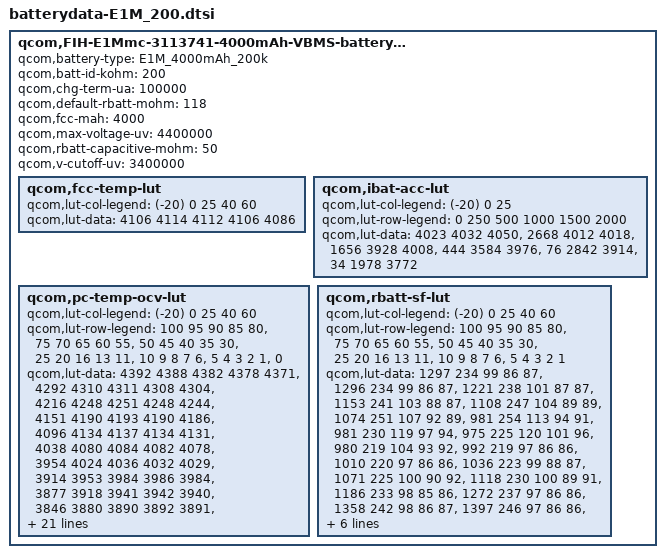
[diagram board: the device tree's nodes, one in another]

qcom,FIH-E1Mmc-3113741-4000mAh-VBMS-batterydata {
	qcom,battery-type = "E1M_4000mAh_200k";
	qcom,batt-id-kohm = <200>;
	qcom,chg-term-ua = <100000>;
	qcom,default-rbatt-mohm = <118>;
	qcom,fcc-mah = <4000>;
	qcom,max-voltage-uv = <4400000>;
	qcom,rbatt-capacitive-mohm = <50>;
	qcom,v-cutoff-uv = <3400000>;

	qcom,fcc-temp-lut {
		qcom,lut-col-legend = <(-20) 0 25 40 60>;
		qcom,lut-data = <4106 4114 4112 4106 4086>;
	};

	qcom,ibat-acc-lut {
		qcom,lut-col-legend = <(-20) 0 25>;
		qcom,lut-row-legend = <0 250 500 1000 1500 2000>;
		qcom,lut-data = <4023 4032 4050>,
				<2668 4012 4018>,
				<1656 3928 4008>,
				<444 3584 3976>,
				<76 2842 3914>,
				<34 1978 3772>;
	};

	qcom,pc-temp-ocv-lut {
		qcom,lut-col-legend = <(-20) 0 25 40 60>;
		qcom,lut-row-legend = <100 95 90 85 80>,
					<75 70 65 60 55>,
					<50 45 40 35 30>,
					<25 20 16 13 11>,
					<10 9 8 7 6>,
					<5 4 3 2 1>,
					<0>;
		qcom,lut-data = <4392 4388 4382 4378 4371>,
				<4292 4310 4311 4308 4304>,
				<4216 4248 4251 4248 4244>,
				<4151 4190 4193 4190 4186>,
				<4096 4134 4137 4134 4131>,
				<4038 4080 4084 4082 4078>,
				<3954 4024 4036 4032 4029>,
				<3914 3953 3984 3986 3984>,
				<3877 3918 3941 3942 3940>,
				<3846 3880 3890 3892 3891>,
				<3822 3850 3854 3854 3852>,
				<3804 3824 3828 3828 3826>,
				<3789 3803 3807 3806 3805>,
				<3776 3786 3790 3790 3788>,
				<3761 3772 3774 3772 3767>,
				<3746 3761 3757 3750 3738>,
				<3728 3744 3738 3730 3716>,
				<3710 3726 3720 3710 3697>,
				<3695 3710 3700 3690 3678>,
				<3682 3702 3690 3682 3670>,
				<3672 3698 3688 3680 3668>,
				<3662 3695 3686 3678 3667>,
				<3650 3691 3685 3677 3665>,
				<3635 3686 3682 3674 3662>,
				<3615 3676 3675 3668 3652>,
				<3590 3656 3656 3648 3626>,
				<3554 3614 3613 3602 3581>,
				<3504 3548 3554 3542 3520>,
				<3422 3458 3464 3460 3436>,
				<3272 3303 3322 3332 3301>,
				<3000 3000 3000 3000 3000>;
	};

	qcom,rbatt-sf-lut {
		qcom,lut-col-legend = <(-20) 0 25 40 60>;
		qcom,lut-row-legend = <100 95 90 85 80>,
					<75 70 65 60 55>,
					<50 45 40 35 30>,
					<25 20 16 13 11>,
					<10 9 8 7 6>,
					<5 4 3 2 1>;
		qcom,lut-data = <1297 234 99 86 87>,
				<1296 234 99 86 87>,
				<1221 238 101 87 87>,
				<1153 241 103 88 87>,
				<1108 247 104 89 89>,
				<1074 251 107 92 89>,
				<981 254 113 94 91>,
				<981 230 119 97 94>,
				<975 225 120 101 96>,
				<980 219 104 93 92>,
				<992 219 97 86 86>,
				<1010 220 97 86 86>,
				<1036 223 99 88 87>,
				<1071 225 100 90 92>,
				<1118 230 100 89 91>,
				<1186 233 98 85 86>,
				<1272 237 97 86 86>,
				<1358 242 98 86 87>,
				<1397 246 97 86 86>,
				<1418 250 97 85 86>,
				<1462 256 98 87 87>,
				<1522 264 99 89 90>,
				<1668 273 103 92 94>,
				<1842 289 105 95 99>,
				<2093 306 109 100 99>,
				<2418 321 108 94 93>,
				<2873 332 103 91 92>,
				<3563 371 106 93 92>,
				<4742 445 113 97 96>,
				<9485 890 225 193 124>;
	};
};
